# BL616/BL618 register map
Vendor: Bouffalo Lab; File version: 1.0
Registers are 32-bit, read-write, reset 0x0 unless marked. A register's access mark holds for its fields unless they carry their own. Offsets are from the block's base; [hi:lo] are bit positions; {n}, {i} and the like mark numbered series; 'fields as' and 'values as' point back to an identical list.

## GLB — Global configuration register
Base 0x20000000
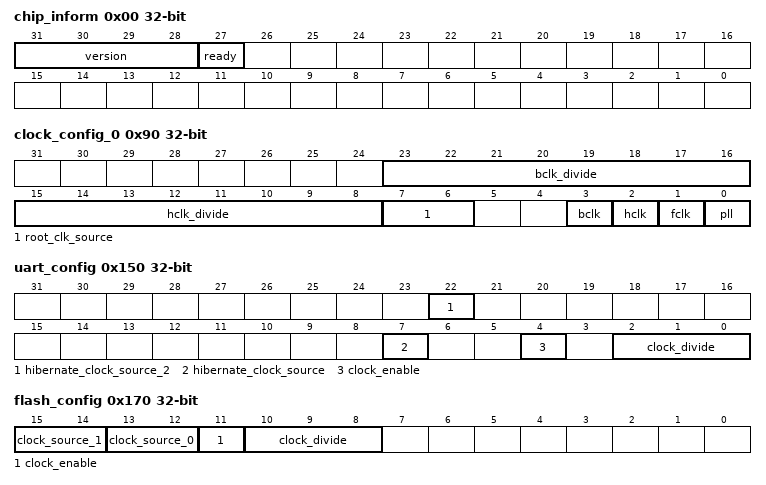
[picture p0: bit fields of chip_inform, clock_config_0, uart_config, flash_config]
0x00 chip_inform — Chip information register
  [31:28] version — Peripheral version
  [27] ready — Chip ready signal
{0x50+4i} interrupt_state[{i}] (i=0..1) — Chip interrupt state register
{0x58+4i} interrupt_mask[{i}] (i=0..1) — Chip interrupt mask register
{0x60+4i} interrupt_clear[{i}] (i=0..1) — Chip clear interrupt register
0x90 clock_config_0 — System clock configuration register 0
  [23:16] bclk_divide — Set divide factor of bus clock
  [15:8] hclk_divide — Set divide factor of hibernate clock
  [7:6] root_clk_source — Set source of root clock
  [3] bclk — Enable or disable bus clock
  [2] hclk — Enable or disable hibernate clock
  [1] fclk — Enable or disable fast clock
  [0] pll — Enable or disable Phase-Locked Loop
0x94 clock_config_1 — System clock configuration register 1
0xA0 bus_config_0 — Bus configuration register 0
0x110 gpadc_config — General Purpose Analog-to-digital convert configuration
{0x120+4i} gpdac_config_{i} (i=0..3) — General Purpose Digital-to-analog convert configuration {i}
{0x130+4i} dma_config_{i} (i=0..2) — Direct Memory Access configuration {i}
0x140 ir_config_0 — Infrared configuration register 0
0x144 ir_config_1 — Infrared configuration register 1
0x150 uart_config — Universal Asynchronous Receiver/Transmitter configuration
  [22] hibernate_clock_source_2 ro — Reads clock source from hibernate registers
  [7] hibernate_clock_source ro — Reads clock source from hibernate registers
  [4] clock_enable — Peripheral level clock gate enable
  [2:0] clock_divide — Peripheral clock divide factor
0x154 uart_signal_0 — Universal Asynchronous Receiver/Transmitter signal configuration 0
  [4n+7:4n] function_0[{n}] (n=0..7) — Select peripheral function for UART signal {n}
    0=uart0_rts (UART0 Request-to-Send flow control); 1=uart0_cts (UART0 Clear-to-Send flow control); 2=uart0_txd (UART0 transmit data); 3=uart0_rxd (UART0 receive data); 4=uart1_rts (UART1 Request-to-Send flow control); 5=uart1_cts (UART1 Clear-to-Send flow control); 6=uart1_txd (UART1 transmit data); 7=uart1_rxd (UART1 receive data)
0x158 uart_signal_1 — Universal Asynchronous Receiver/Transmitter signal configuration 1
  [4n+7:4n] function_1[{n}] (n=0..3) — Select peripheral function for UART signal {n} (offset by 8)
    values as uart_signal_0.function_0[0]
0x170 flash_config — Serial flash configuration
  [15:14] clock_source_1 — Peripheral clock source register 1
  [13:12] clock_source_0 — Peripheral clock source register 0
  [11] clock_enable — Peripheral level clock gate enable
  [10:8] clock_divide — Peripheral clock divide factor
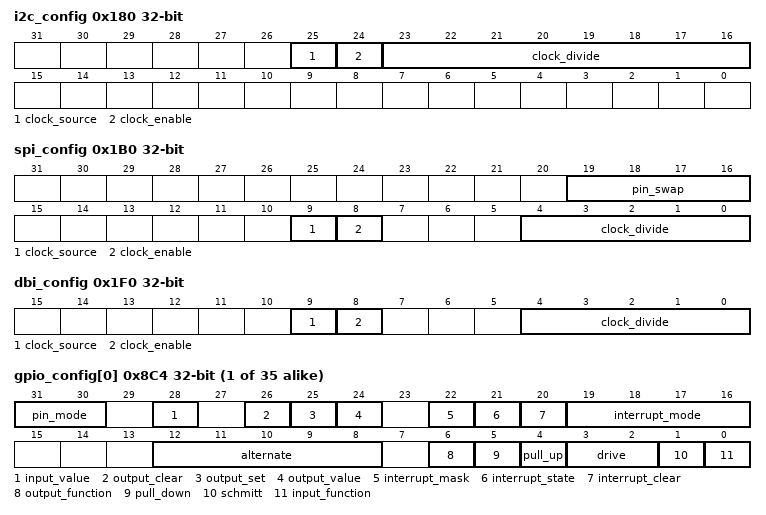
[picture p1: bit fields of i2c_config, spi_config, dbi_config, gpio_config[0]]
0x180 i2c_config — Inter-Integrated Circuit bus configuration
  [25] clock_source — Peripheral clock source register
  [24] clock_enable — Peripheral level clock gate enable
  [23:16] clock_divide — Peripheral clock divide factor
0x190 i2s_config — Inter-IC Sound configuration
0x1B0 spi_config — Serial Peripheral Interface configuration
  [19:16] pin_swap — Swap Serial Peripheral Interface pin signals
  [9] clock_source — Peripheral clock source register
  [8] clock_enable — Peripheral level clock gate enable
  [4:0] clock_divide — Peripheral clock divide factor
0x1E0 pwm_config — Pulse-Width configuration
0x1F0 dbi_config — MIPI Display Bus Interface clock configuration
  [9] clock_source — Peripheral clock source register
  [8] clock_enable — Peripheral level clock gate enable
  [4:0] clock_divide — Peripheral clock divide factor
{0x250+4i} digit_clock_{i} (i=0..2) — Digital clock configuration {i}
0x260 radio_config — Radio frequency configuration register
{0x2E0+4i} debug_config_{i} (i=0..4) — Debug configuration register {i}
0x300 self_test_0 — Machine Built-in Self Test register 0
0x304 self_test_1 — Machine Built-in Self Test register 1
0x340 audio_config_0 — Audio configuration register 0
0x344 audio_config_1 — Audio configuration register 1
0x390 emac_config — Ethernet Media Access Control configuration
0x430 sdh_config — Secure Digital host configuration
0x490 permit_config — Permission control peripheral configuration
0x620 psram_config — Pseudo Static Random-Access Memory configuration
{0x810+4i} wifi_pll_config_{i} (i=0..14) — Wireless Fidelity Phase-Locked Loop configuration {i}
0x884 ldo18 — 1.8-V Low Dropout Linear Regulator configuration
{0x8C4+4i} gpio_config[{i}] (i=0..34) — Generic Purpose Input/Output config
  [31:30] pin_mode — Pin input/output mode switch
    0=output_value (Output by `output_value` field); 1=set_clear (Output set by `output_set` and `output_clear` fields); 2=dma_output_value (Source from GPIO DMA, output by `output_value`); 3=dma_set_clear (Source from GPIO DMA, set by `output_set` and `output_clear`)
  [28] input_value ro
  [26] output_clear wo — Clear output value to 0 . When sets and clears at the same, only set will take effect.
  [25] output_set wo — Set output value to 1 . When sets and clears at the same, only set will take effect.
  [24] output_value
  [22] interrupt_mask — Pin interrupt mask
  [21] interrupt_state ro — Pin interrupt state
  [20] interrupt_clear — Clear pin interrupt flag
  [19:16] interrupt_mode — Select pin interrupt mode
    0=sync_falling_edge (Synchronous interrupt in falling edge); 1=sync_rising_edge (Synchronous interrupt in rising edge); 2=sync_low_level (Synchronous interrupt in low level); 3=sync_high_level (Synchronous interrupt in high level); 4=sync_both_edges (Synchronous interrupt in both rising and falling edges); 8=async_falling_edge (Asynchronous interrupt in falling edge); 9=async_rising_edge (Asynchronous interrupt in rising edge); 10=async_low_level (Asynchronous interrupt in low level); 11=async_high_level (Asynchronous interrupt in high level)
  [12:8] alternate — Pin alternate function switch
    0=sdh (Secure Digital host); 1=spi0 (Serial Peripheral Interface 0); 2=Flash control; 3=i2s0 (Inter-IC Sound 0); 4=pdm (Pulse Density Modulation); 5=i2c0 (Inter-Integrated Circuit bus 0); 6=i2c1 (Inter-Integrated Circuit bus 1); 7=uart0 (Universal Asynchronous Receiver/Transmitter 0); 8=emac (Ethernet Media Access Control); 9=cam; 10=analog; 11=gpio (Generic Purpose Input/Output); 12=sdio; 16=pwm0 (Pulse-Width Modulation module 0); 17=jtag; 18=uart1 (Universal Asynchronous Receiver/Transmitter 1); 19=pwm1 (Pulse-Width Modulation 1); 20=spi1 (Serial Peripheral Interface 1); 21=i2s1 (Inter-IC Sound 1); 22=dbi_b; 23=dbi_c; 24=qspi; 25=apwm (Audio Pulse-Width Modulation); 31=Clock output
  [6] output_function — Enable output signal
  [5] pull_down — Enable internal pull-down
  [4] pull_up — Enable internal pull-up
  [3:2] drive — Drive strength
  [1] schmitt — Enable schmitt trigger
  [0] input_function — Enable input signal
{0xAC4+4i} gpio_input[{i}] (i=0..1) — Read value from Generic Purpose Input/Output pins
{0xAE4+4i} gpio_output[{i}] (i=0..1) — Write value to Generic Purpose Input/Output pins
{0xAEC+4i} gpio_set[{i}] (i=0..1) — Set pin output value to high
{0xAF4+4i} gpio_clear[{i}] (i=0..1) — Set pin output value to low
